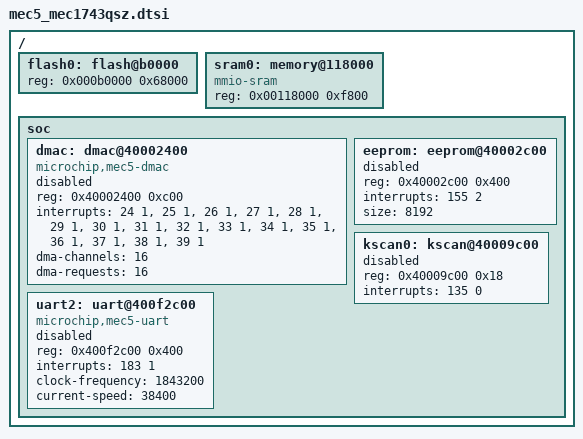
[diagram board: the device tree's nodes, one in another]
/*
 * Copyright (c) 2024 Microchip Technology Inc.
 *
 * SPDX-License-Identifier: Apache-2.0
 */

#include <arm/armv7-m.dtsi>

#include "mec5.dtsi"
#include "mec5/mec5_mec174xsz-espi-host-dev.dtsi"

/ {
	flash0: flash@b0000 {
		reg = <0x000b0000 0x68000>;
	};

	sram0: memory@118000 {
		compatible = "mmio-sram";
		reg = <0x00118000 0xf800>;
	};

	soc {
		#include "mec5/mec5_gpspi_v2.dtsi"

		dmac: dmac@40002400 {
			compatible = "microchip,mec5-dmac";
			reg = <0x40002400 0xc00>;
			interrupts = <24 1>, <25 1>, <26 1>, <27 1>,
				     <28 1>, <29 1>, <30 1>, <31 1>,
				     <32 1>, <33 1>, <34 1>, <35 1>,
				     <36 1>, <37 1>, <38 1>, <39 1>;
			#dma-cells = <2>;
			dma-channels = <16>;
			dma-requests = <16>;
			status = "disabled";
		};

		eeprom: eeprom@40002c00 {
			reg = <0x40002c00 0x400>;
			interrupts = <155 2>;
			size = <8192>;
			status = "disabled";
		};

		kscan0: kscan@40009c00 {
			reg = <0x40009c00 0x18>;
			interrupts = <135 0>;
			status = "disabled";
		};

		/* Yet another exception. After MEC172x the 144-pin package has 3 UARTs */
		uart2: uart@400f2c00 {
			compatible = "microchip,mec5-uart";
			reg = <0x400f2c00 0x400>;
			interrupts = <183 1>;
			clock-frequency = <1843200>;
			current-speed = <38400>;
			status = "disabled";
		};
	};
};
